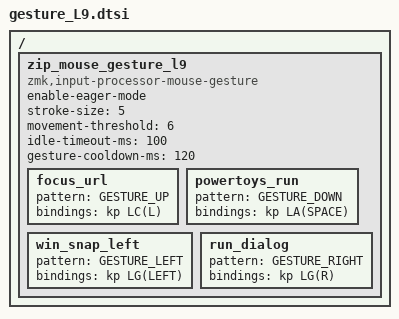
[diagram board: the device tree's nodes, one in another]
/ {
  zip_mouse_gesture_l9: zip_mouse_gesture_l9 {
    compatible = "zmk,input-processor-mouse-gesture";
    #input-processor-cells = <0>;  
    enable-eager-mode;
    stroke-size = <5>;
    movement-threshold = <6>;
    idle-timeout-ms = <100>;
    gesture-cooldown-ms = <120>;

    focus_url        { pattern = <GESTURE_UP>;    bindings = <&kp LC(L)>;      };  // URLバー選択
    powertoys_run    { pattern = <GESTURE_DOWN>;  bindings = <&kp LA(SPACE)>; };  // PowerToys Run
    win_snap_left    { pattern = <GESTURE_LEFT>;  bindings = <&kp LG(LEFT)>;  };  // ウィンドウ左スナップ
    run_dialog       { pattern = <GESTURE_RIGHT>; bindings = <&kp LG(R)>;     };  // Runダイアログ
  };
};
